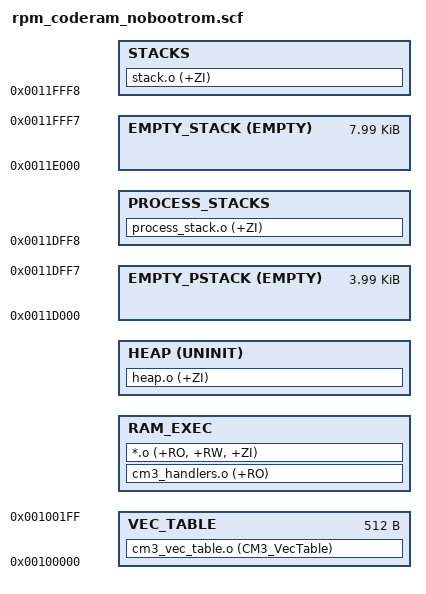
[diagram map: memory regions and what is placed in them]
;************************************************************************
;;; Copyright ARM Ltd 2001. All rights reserved.
;
; This scatterloading descriptor file defines: one load region (ROM_LOAD) 
; and five execution regions (ROM_EXEC, RAM, PAGETABLE, HEAP, STACKS).
;
; The entire program (code & data) is placed in ROM at ROM_LOAD.
;
; The RO code will execute from ROM_EXEC.  Its execution address (0x0) is the same
; as its load address (0x0), so it does not need to be moved (a 'root region').
; The exception vector table (AREA Vect in vectors.s) must appear at 0x0, so is 
; placed '+First' in the image.
;
; The RW data will get relocated (copied) from ROM_LOAD to RAM at 0x18000000.
; The ZI data will get created (initialized) in RAM, above the RW data.
;
; The region PAGETABLE is used to locate the start of the pagetable immediately
; above the RAM region.  This table should be 16k is size.
 
; The region HEAP is used to locate the bottom of the heap immediately above 
; the ZI data ("+0"). The heap will grow up from this address.
;
; The region STACKS is used to locate the top of the memory used to store
; the stacks for each mode. The stacks will grow down from this address.
;
; Regions marked UNINIT will be left uninitialized, i.e. they will not be 
; zero-initialized by the C library when it starts-up.

; **************************
CODE_RAM  0x00100000 0x20000
{
    VEC_TABLE 0x00100000 0x200
    {
        cm3_vec_table.o (CM3_VecTable)
    }
    RAM_EXEC +0
    {
        cm3_handlers.o (+RO)
        *.o (+RO, +RW, +ZI)
    }
    HEAP +0 UNINIT
    {
        heap.o (+ZI)
    }
    EMPTY_PSTACK 0x0011DFF8   EMPTY -0xFF8
    {

    }
    PROCESS_STACKS 0x0011DFF8
    {
        process_stack.o (+ZI)
    }
    EMPTY_STACK 0x0011FFF8    EMPTY -0x1FF8
    {

    }
    STACKS 0x0011FFF8
    {
        stack.o (+ZI)
    }
}

